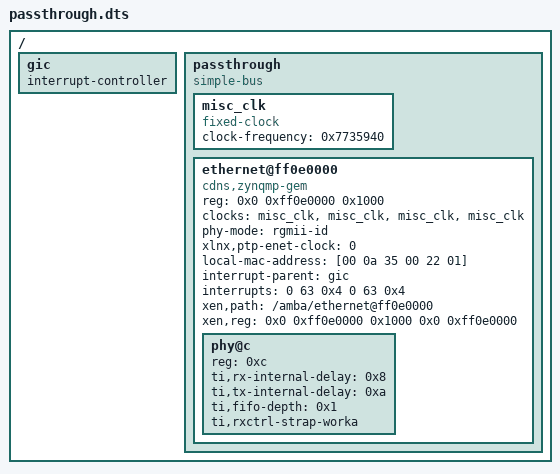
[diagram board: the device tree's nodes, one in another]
/dts-v1/;

/ {
    #address-cells = <2>;
    #size-cells = <1>;

    gic: gic {
        #interrupt-cells = <3>;
        interrupt-controller;
    };

    passthrough {
        compatible = "simple-bus";
        ranges;
        #address-cells = <2>;
        #size-cells = <1>;

        misc_clk: misc_clk {
            #clock-cells = <0>;
            clock-frequency = <0x7735940>;
            compatible = "fixed-clock";
        };

        ethernet@ff0e0000 {
            compatible = "cdns,zynqmp-gem";
            status = "okay";
            reg = <0x0 0xff0e0000 0x1000>;
            clock-names = "pclk", "hclk", "tx_clk", "rx_clk";
            #address-cells = <1>;
            #size-cells = <0>;
            clocks = <&misc_clk &misc_clk &misc_clk &misc_clk>;
            phy-mode = "rgmii-id";
            xlnx,ptp-enet-clock = <0>;
            local-mac-address = [00 0a 35 00 22 01];
            interrupt-parent = <&gic>;
            interrupts = <0 63 0x4 0 63 0x4>;
            xen,path = "/amba/ethernet@ff0e0000";
            xen,reg = <0x0 0xff0e0000 0x1000 0x0 0xff0e0000>;

            phy@c {
                reg = <0xc>;
                ti,rx-internal-delay = <0x8>;
                ti,tx-internal-delay = <0xa>;
                ti,fifo-depth = <0x1>;
                ti,rxctrl-strap-worka;
            };
        };
    };
};
